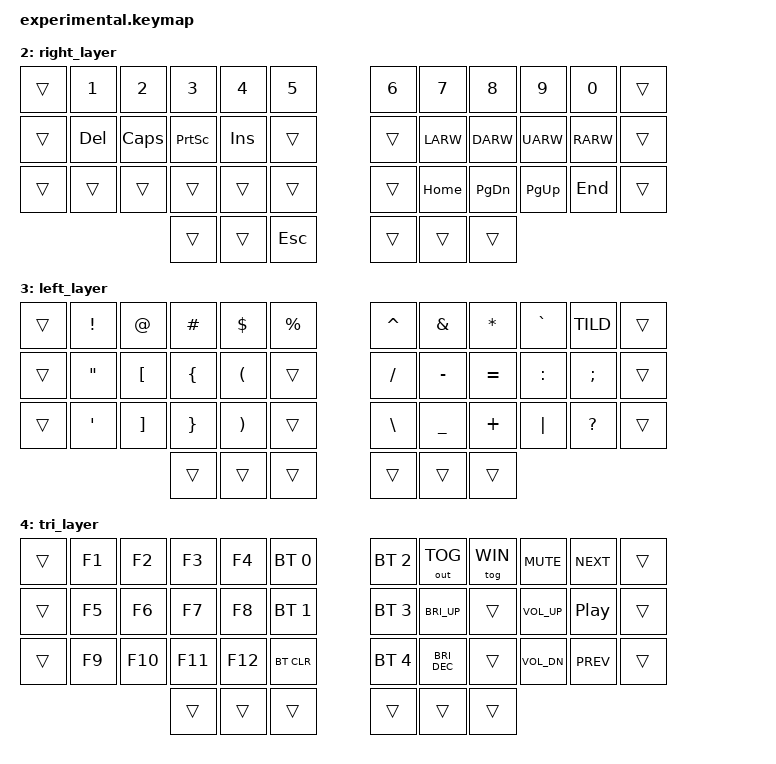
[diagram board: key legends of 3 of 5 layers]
/*
 * Copyright (c) 2020 The ZMK Contributors
 *
 * SPDX-License-Identifier: MIT
 */

#include <behaviors.dtsi>
#include <dt-bindings/zmk/keys.h>
#include <dt-bindings/zmk/bt.h>
#include <dt-bindings/zmk/outputs.h>

// Home row mods macro
// mac: LALT(ctrl) LCTRL(OPT) LGUI(CMD)
// win: LCTRL LGUI LALT 

#define HRML(k2,k3,k4) &ht LALT k2  &ht LCTRL k3  &ht LGUI k4
#define HRMR(k1,k2,k3) &ht RGUI k1  &ht RCTRL k2  &ht RALT k3
#define WHRML(k2,k3,k4) &ht LALT k2  &ht LGUI k3  &ht LCTRL k4
#define WHRMR(k1,k2,k3) &ht RCTRL k1  &ht RGUI k2  &ht RALT k3

#define MAC 0
#define WIN 1
#define RIG 2
#define LEF 3
#define TRI 4

/ {
    behaviors {
        ht: hold_tap {
            label = "hold_tap";
            compatible = "zmk,behavior-hold-tap";
            #binding-cells = <2>;
            flavor = "tap-preferred";
            tapping-term-ms = <220>;
            quick-tap-ms = <150>;
            global-quick-tap;
            bindings = <&kp>, <&kp>;
        };
    };

    conditional_layers {
        compatible = "zmk,conditional-layers";
        tri_layer {
            if-layers = <RIG LEF>;
            then-layer = <TRI>;
        };
    };

    keymap {
        compatible = "zmk,keymap";
        default_layer {
            bindings = <
        //╭──────────┬──────────┬──────────┬──────────┬──────────┬──────────╮   ╭──────────┬──────────┬──────────┬──────────┬──────────┬──────────╮
        //│          │  Q       │  W       │  E       │  R       │  T       │   │  Y       │  U       │  I       │  O       │  P       │          │
            &trans     &kp Q      &kp W      &kp E      &kp R      &kp T          &kp Y      &kp U      &kp I      &kp O      &kp P      &trans    
        //├──────────┼──────────┼──────────┼──────────┼──────────┼──────────┤   ├──────────┼──────────┼──────────┼──────────┼──────────┼──────────┤
        //│          │  A       │  S       │  D       │  F       │  G       │   │  H       │  J       │  K       │  L       │BACKSPACE │          │
            &trans     &kp A     HRML(S,         D,         F)     &kp G          &kp H      HRMR(J,        K,           L)   &kp BSPC   &trans    
        //├──────────┼──────────┼──────────┼──────────┼──────────┼──────────┤   ├──────────┼──────────┼──────────┼──────────┼──────────┼──────────┤
        //│          │  Z       │  X       │  C       │  V       │  B       │   │  N       │  M       │ , <      │ . >      │ ENTER    │          │
            &trans     &kp Z      &kp X      &kp C      &kp V      &kp B          &kp N      &kp M      &kp COMMA  &kp DOT    &kp ENTER  &trans    
        //╰──────────┴──────────┴──────────┼──────────┼──────────┼──────────┤   ├──────────┼──────────┼──────────┼──────────┴──────────┴──────────╯
                                             &trans   &lt LEF TAB  &kp LSHIFT    &kp SPACE  &lt RIG TAB  &trans   
        //                                 ╰──────────┴──────────┴──────────╯   ╰──────────┴──────────┴──────────╯
            >;
        };

        windows_layer {
            bindings = <
        //╭──────────┬──────────┬──────────┬──────────┬──────────┬──────────╮   ╭──────────┬──────────┬──────────┬──────────┬──────────┬──────────╮
        //│          │  Q       │  W       │  E       │  R       │  T       │   │  Y       │  U       │  I       │  O       │  P       │          │
            &trans     &kp Q      &kp W      &kp E      &kp R      &kp T          &kp Y      &kp U      &kp I      &kp O      &kp P      &trans    
        //├──────────┼──────────┼──────────┼──────────┼──────────┼──────────┤   ├──────────┼──────────┼──────────┼──────────┼──────────┼──────────┤
        //│          │  A       │  S       │  D       │  F       │  G       │   │  H       │  J       │  K       │  L       │BACKSPACE │          │
            &trans     &kp A    WHRML(S,         D,         F)     &kp G          &kp H      WHRMR(J,        K,         L)   &kp BSPC    &trans    
        //├──────────┼──────────┼──────────┼──────────┼──────────┼──────────┤   ├──────────┼──────────┼──────────┼──────────┼──────────┼──────────┤
        //│          │  Z       │  X       │  C       │  V       │  B       │   │  N       │  M       │ , <      │ . >      │ ENTER    │          │
            &trans     &kp Z      &kp X      &kp C      &kp V      &kp B          &kp N      &kp M      &kp COMMA  &kp DOT    &kp ENTER  &trans    
        //╰──────────┴──────────┴──────────┼──────────┼──────────┼──────────┤   ├──────────┼──────────┼──────────┼──────────┴──────────┴──────────╯
                                             &trans   &lt LEF TAB  &kp LSHIFT    &kp SPACE  &lt RIG TAB  &trans   
        //                                 ╰──────────┴──────────┴──────────╯   ╰──────────┴──────────┴──────────╯
            >;
        };

        right_layer {
            bindings = <
        //╭──────────┬──────────┬──────────┬──────────┬──────────┬──────────╮   ╭──────────┬──────────┬──────────┬──────────┬──────────┬──────────╮
        //│          │ 1        │  2       │  3       │  4       │  5       │   │ 6        │ 7        │ 8        │ 9        │   0      │          │
            &trans     &kp N1    &kp N2     &kp N3     &kp N4     &kp N5          &kp N6     &kp N7     &kp N8     &kp N9      &kp N0    &trans    
        //├──────────┼──────────┼──────────┼──────────┼──────────┼──────────┤   ├──────────┼──────────┼──────────┼──────────┼──────────┼──────────┤
        //│          │ DELETE   │ CapsLock │ PrintSc  │  INSERT  │          |   |          │ LEFT     │ DOWN     │ UP       │ RIGHT    │          │
            &trans     &kp DEL   &kp CAPS   &kp PSCRN  &kp INS     &trans          &trans    &kp LARW   &kp DARW   &kp UARW   &kp RARW   &trans    
        //├──────────┼──────────┼──────────┼──────────┼──────────┼──────────┤   ├──────────┼──────────┼──────────┼──────────┼──────────┼──────────┤
        //│          │          │          │          │          │          │   │          │ HOME     │ PAGEn DN  │ PAGE UP  │ END      │          │
            &trans     &trans    &trans     &trans     &trans      &trans           &trans   &kp HOME   &kp PG_DN  &kp PG_UP  &kp END    &trans    
        //╰──────────┴──────────┴──────────┼──────────┼──────────┼──────────┤   ├──────────┼──────────┼──────────┼──────────┴──────────┴──────────╯
                                             &trans     &trans     &kp ESC        &trans     &trans      &trans   
        //                                 ╰──────────┴──────────┴──────────╯   ╰──────────┴──────────┴──────────╯
            >;
        };

        left_layer {
            bindings = <
        //╭──────────┬──────────┬──────────┬──────────┬──────────┬──────────╮   ╭──────────┬──────────┬──────────┬──────────┬──────────┬──────────╮
        //│          │  !       │  @       │  #       │  $       │  %       │   │  ^       │  &       │  *       │  `       │  ~       │          │
            &trans     &kp EXCL   &kp AT     &kp HASH   &kp DLLR   &kp PRCNT      &kp CARET  &kp AMPS   &kp ASTRK  &kp GRAVE   &kp TILD  &trans    
        //├──────────┼──────────┼──────────┼──────────┼──────────┼──────────┤   ├──────────┼──────────┼──────────┼──────────┼──────────┼──────────┤
        //│          │  "       │  [       │  {       │  (       │          │   │   /      │  -       │  =       │     :    │  ;       │          │
            &trans     &kp DQT  &kp LBKT   &kp LBRC   &kp LPAR   &trans         &kp FSLH   &kp MINUS  &kp EQUAL  &kp COLON   &kp SEMI    &trans    
        //├──────────┼──────────┼──────────┼──────────┼──────────┼──────────┤   ├──────────┼──────────┼──────────┼──────────┼──────────┼──────────┤
        //│          │  '       │  ]       │  }       │  )       │          │   │    \     │  _       │  +       │  │       │   ?      │          │
            &trans     &kp SQT     &kp RBKT   &kp RBRC   &kp RPAR   &trans         &kp BSLH   &kp UNDER  &kp PLUS   &kp PIPE  &kp QMARK  &trans    
        //╰──────────┴──────────┴──────────┼──────────┼──────────┼──────────┤   ├──────────┼──────────┼──────────┼──────────┴──────────┴──────────╯
                                             &trans     &trans     &trans         &trans     &trans      &trans   
        //                                 ╰──────────┴──────────┴──────────╯   ╰──────────┴──────────┴──────────╯
            >;
        };

        tri_layer {
            bindings = <
        //╭──────────┬──────────┬──────────┬──────────┬───────────┬────────────╮   ╭────────────┬────────────┬──────────┬───────────┬──────────┬──────────╮
        //│          │  F1      │  F2      │  F3      │  F4       │ PROFILE 0  │   │ PROFILE 2  │ TOGGLEOUT  │ WINDOWS  │ VOL MUTE  │ NEXTSONG │          │
            &trans     &kp F1     &kp F2     &kp F3     &kp F4     &bt BT_SEL 0     &bt BT_SEL 2  &out OUT_TOG &tog WIN  &kp C_MUTE  &kp C_NEXT    &trans  
        //├──────────┼──────────┼──────────┼──────────┼───────────┼────────────┤   ├────────────┼────────────┼──────────┼───────────┼──────────┼──────────┤
        //│          │  F5      │  F6      │  F7      │  F8       │ PROFILE 1  │   │ PROFILE 3  │ INC BRIGHT │          │  VOL UP   │PAUSEMUSIC│          │
            &trans     &kp F5     &kp F6     &kp F7     &kp F8     &bt BT_SEL 1     &bt BT_SEL 3  &kp C_BRI_UP  &trans   &kp C_VOL_UP  &kp C_PP    &trans  
        //├──────────┼──────────┼──────────┼──────────┼───────────┼────────────┤   ├────────────┼────────────┼──────────┼───────────┼──────────┼──────────┤
        //│          │  F9      │  F10     │  F11     │  F12      │  CLEAR BT  │   │ PROFILE 4  │ DEC BRIGHT │          |  VOL DOWN │ PREVSONG │          │
            &trans     &kp F9     &kp F10    &kp F11    &kp F12     &bt BT_CLR      &bt BT_SEL 4  &kp C_BRI_DEC  &trans   &kp C_VOL_DN &kp C_PREV  &trans  
        //╰──────────┴──────────┴──────────┼──────────┼───────────┼────────────┤   ├────────────┼────────────┼──────────┼───────────┴──────────┴──────────╯
                                             &trans      &trans      &trans          &trans       &trans         &trans  
        //                                 ╰──────────┴───────────┴────────────╯   ╰────────────┴────────────┴──────────╯
            >;
        };
    };
};
